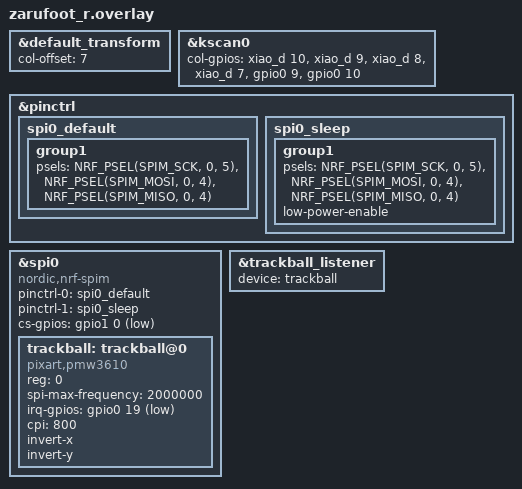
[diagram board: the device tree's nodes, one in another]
#include "zarufoot.dtsi"
//#include <dt-bindings/zmk/input_transform.h>


// matrix transformでのピン数オフセット
&default_transform { // Offset of 7 because the left side has 2 columns
    col-offset = <7>;
};

// kscan
&kscan0 {
    col-gpios = 
        <&xiao_d 10 GPIO_ACTIVE_HIGH>,
        <&xiao_d 9 GPIO_ACTIVE_HIGH>,
        <&xiao_d 8 GPIO_ACTIVE_HIGH>,
        <&xiao_d 7 GPIO_ACTIVE_HIGH>,
        <&gpio0 9 GPIO_ACTIVE_HIGH>,
        <&gpio0 10 GPIO_ACTIVE_HIGH>;
};

/* * コメントアウトされた古い設定 (参考用)
 */
// pmw3610用
// &xiao_spi {
//     // compatible = "nordic,nrf-spim";
//     status = "okay";
//     cs-gpios = <&gpio1 0 GPIO_ACTIVE_LOW>;

//     trackball: trackball@0 {
//         compatible = "pixart,pmw3610";
//         reg = <0>;
//         spi-max-frequency = <2000000>;
//         status = "okay";
//         irq-gpios = <&gpio0 16 (GPIO_ACTIVE_LOW | GPIO_PULL_UP)>; // MOTION (defaultではdr-gpio)

//         sensitivity = "2x";
//         sleep;
//         no-taps;
//     };
// };

// // Overrides for the input listener node in .dtsi
// &trackball_listener {
//     status = "okay";
//     device = <&trackball>;
//     //Input Processor XとY方向を逆転している
//     // input-processors = <&zip_xy_transform (INPUT_TRANSFORM_X_INVERT | INPUT_TRANSFORM_Y_INVERT)>;
// };


/*
 * SPI と トラックボール の設定
 */
&pinctrl {
    spi0_default: spi0_default {
        group1 {
            psels = <NRF_PSEL(SPIM_SCK, 0, 5)>     // SCLK
                  , <NRF_PSEL(SPIM_MOSI, 0, 4)>   // SDIO
                  , <NRF_PSEL(SPIM_MISO, 0, 4)>   // SDIO
                  ;
        };
    };

    spi0_sleep: spi0_sleep {
        group1 {
            psels = <NRF_PSEL(SPIM_SCK, 0, 5)>     // SCLK
                  , <NRF_PSEL(SPIM_MOSI, 0, 4)>   // SDIO
                  , <NRF_PSEL(SPIM_MISO, 0, 4)>   // SDIO
                  ;
            low-power-enable;
        };
    };
};

&spi0 {
    status = "okay";
    compatible = "nordic,nrf-spim";
    pinctrl-0 = <&spi0_default>;
    pinctrl-1 = <&spi0_sleep>;
    pinctrl-names = "default", "sleep";
    cs-gpios = <&gpio1 0 GPIO_ACTIVE_LOW>; // CS

    trackball: trackball@0 {
        status = "okay";
        compatible = "pixart,pmw3610";
        reg = <0>;
        spi-max-frequency = <2000000>;
        irq-gpios = <&gpio0 19 (GPIO_ACTIVE_LOW | GPIO_PULL_UP)>; //MOT
        
        /* === badjeff版ドライバー用の設定 === */
        
        // .conf の CONFIG_PMW3610_CPI=800 から移行
        cpi = <800>;

        // .conf の CONFIG_PMW3610_INVERT_X=y から移行
        invert-x;

        // .conf の CONFIG_PMW3610_INVERT_Y=y から移行
        invert-y;

        /* * snipe-layers と scroll-layers は badjeff 版では削除されました。
         * これらの機能は .keymap ファイルで
         * &input_listener のレイヤーバインディング (&input_rel_cpi_set, &input_rel_scroll) 
         * を使って設定する必要があります。
         */
        // snipe-layers = <4>;       <-- 削除
        // scroll-layers = <5 6 7>; <-- 削除
    };
};

&trackball_listener {
    status = "okay";
    device = <&trackball>;
};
